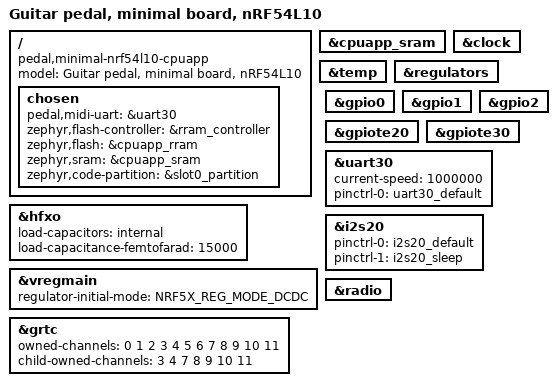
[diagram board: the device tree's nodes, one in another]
/dts-v1/;

#include <nordic/nrf54l10_cpuapp.dtsi>
#include <zephyr/dt-bindings/regulator/nrf5x.h>
#include "minimal-pinctrl.dtsi"

/ {
	compatible = "pedal,minimal-nrf54l10-cpuapp";
	model = "Guitar pedal, minimal board, nRF54L10";

	chosen {
		/*
		 * uart30 carries MIDI and has no console on it, so it is
		 * named here rather than as zephyr,console.  There is no
		 * console anywhere - prj.conf says why.
		 */
		pedal,midi-uart = &uart30;
		zephyr,flash-controller = &rram_controller;
		zephyr,flash = &cpuapp_rram;
		zephyr,sram = &cpuapp_sram;
		zephyr,code-partition = &slot0_partition;
	};
};

&cpuapp_sram {
	status = "okay";
};

/*
 * There is no 32.768 kHz crystal on this board: Y501 is the 32 MHz part
 * and XL1/XL2 go nowhere, so the low-frequency clock is the internal RC
 * and lfxo is left alone.  The defconfig is where that is selected.
 */
/*
 * Y501 is 32MHz/8pF/20ppm in a 2016 package and the board carries no
 * external load capacitors.  The value below, in femtofarads, is CINT,
 * the capacitor on each pin, which is what the datasheet's INTCAP
 * equation takes - not the load the crystal sees.  The crystal sees the
 * two pins in series, about (CINT + Cpcb) / 2, so an 8 pF crystal needs
 * CINT near 2 x 8 less the board's stray capacitance.  Below about 10 pF
 * here the radio loses connections: its packets go unheard.
 */
&hfxo {
	load-capacitors = "internal";
	load-capacitance-femtofarad = <15000>;
};

/*
 * The clock controller has to be enabled for the low-frequency source
 * to be selectable at all: without it CLOCK_CONTROL_NRF is off, the
 * whole K32SRC choice disappears, and a Bluetooth build stops at
 * MPSL's "Clock source is not supported or not defined".
 */
&clock {
	status = "okay";
};

&temp {
	status = "okay";
};

&regulators {
	status = "okay";
};

/* L501, 4.7uH from DCC to DECD, is what makes this mode available. */
&vregmain {
	status = "okay";
	regulator-initial-mode = <NRF5X_REG_MODE_DCDC>;
};

&grtc {
	owned-channels = <0 1 2 3 4 5 6 7 8 9 10 11>;
	child-owned-channels = <3 4 7 8 9 10 11>;
	status = "okay";
};

&gpio0 {
	status = "okay";
};

&gpio1 {
	status = "okay";
};

&gpio2 {
	status = "okay";
};

&gpiote20 {
	status = "okay";
};

&gpiote30 {
	status = "okay";
};

/*
 * P1.02 and P1.03 are NFC1 and NFC2 and come up as an NFC antenna after
 * every reset.  Freeing them is app/src/pins.c, not the devicetree
 * property that looks like it would do it - see the comment there.
 */

/*
 * The only way in or out.  No driver: app/src/main.c sets the registers
 * itself, and takes the pins and speed from here.  1 Mbit is far more than
 * the MIDI it carries needs; the point of the speed is that a bulk
 * transfer does not hold up a note.
 */
&uart30 {
	status = "okay";
	current-speed = <1000000>;
	pinctrl-0 = <&uart30_default>;
	pinctrl-names = "default";
};

/* The audio link from the RP2354, received as a slave: app/src/audio.c */
&i2s20 {
	status = "okay";
	pinctrl-0 = <&i2s20_default>;
	pinctrl-1 = <&i2s20_sleep>;
	pinctrl-names = "default", "sleep";
};

&radio {
	status = "okay";
};

#include <vendor/nordic/nrf54l10_cpuapp_partition.dtsi>
